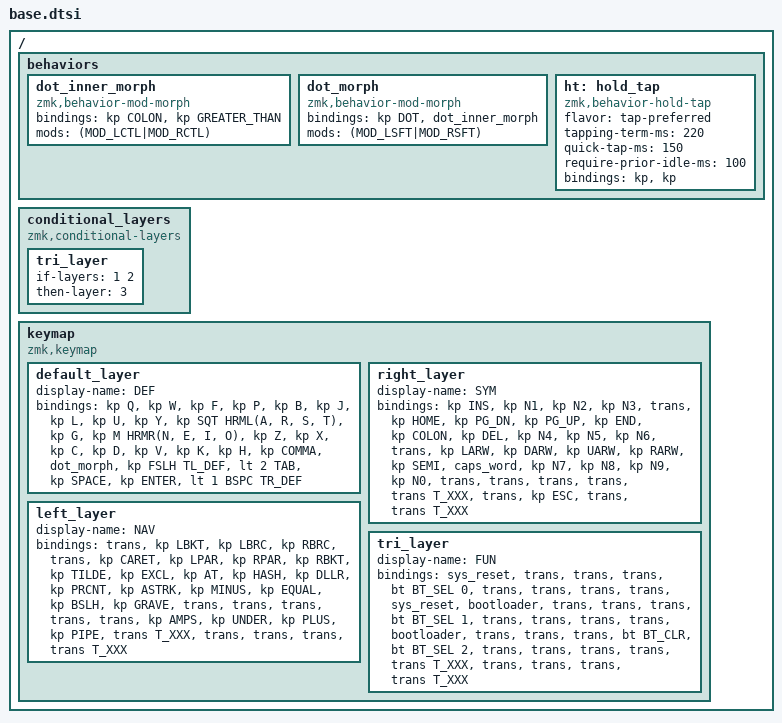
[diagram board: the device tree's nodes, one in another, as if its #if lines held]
// vim: set ts=2 sw=2 ft=devicetree:

#include <behaviors.dtsi>
#include <dt-bindings/zmk/keys.h>
#include <dt-bindings/zmk/bt.h>

//layers definitions
#define DEF 0
#define SYM 1
#define NAV 2
#define FUN 3

// Now import if any extra external layers needed
#include "combos.dtsi"

#ifdef THREE_THUMBS
#  define TL_DEF &mt LGUI TAB
#  define TR_DEF &mt RALT DEL
#  define T_XXX &none
#else
#  define TL_DEF
#  define TR_DEF
#  define T_XXX
#endif

// Home row mods macro
// GUI -> ALT -> CTRL -> SHFT    |    SHFT -> CTRL -> ALT -> GUI
#define HRML(k1,k2,k3,k4) &ht LGUI  k1 &ht LALT  k2 &ht LCTRL k3 &ht LSHFT k4
#define HRMR(k1,k2,k3,k4) &ht RSHFT k1 &ht RCTRL k2 &ht RALT  k3 &ht RGUI  k4

// tap: dot | shift + tap: colon | ctrl + shift + tap: >
/ {
    behaviors {
        dot_inner_morph: dot_inner_morph {
            compatible = "zmk,behavior-mod-morph";
            bindings = <&kp COLON>, <&kp GREATER_THAN>;
            mods = <(MOD_LCTL|MOD_RCTL)>;
        };
        dot_morph: dot_morph {
            compatible = "zmk,behavior-mod-morph";
            bindings = <&kp DOT>, <&dot_inner_morph>;
            mods = <(MOD_LSFT|MOD_RSFT)>;
        };
    };
};

/ {
    behaviors {
        ht: hold_tap {
            compatible = "zmk,behavior-hold-tap";
            #binding-cells = <2>;
            flavor = "tap-preferred";
            tapping-term-ms = <220>;
            quick-tap-ms = <150>;
            require-prior-idle-ms = <100>;
            bindings = <&kp>, <&kp>;
        };
    };

    conditional_layers {
        compatible = "zmk,conditional-layers";
        tri_layer {
            if-layers = <1 2>;
            then-layer = <3>;
        };
    };

    keymap {
        compatible = "zmk,keymap";
        default_layer {
            display-name = "DEF";
            bindings = <
        //╭──────────┬──────────┬──────────┬──────────┬──────────╮   ╭──────────┬──────────┬──────────┬──────────┬──────────╮
            &kp Q      &kp W      &kp F      &kp P      &kp B          &kp J      &kp L      &kp U      &kp Y      &kp SQT
        //├──────────┼──────────┼──────────┼──────────┼──────────┤   ├──────────┼──────────┼──────────┼──────────┼──────────┤
            HRML(A,        R,         S,         T)     &kp G          &kp M      HRMR(N,        E,         I,        O)
        //├──────────┼──────────┼──────────┼──────────┼──────────┤   ├──────────┼──────────┼──────────┼──────────┼──────────┤
            &kp Z      &kp X      &kp C      &kp D      &kp V          &kp K      &kp H      &kp COMMA  &dot_morph &kp FSLH
        //╰──────────┴──────────┴──────────┼──────────┼──────────┤   ├──────────┼──────────┼──────────┴──────────┴──────────╯
                                  TL_DEF    &lt 2 TAB   &kp SPACE     &kp ENTER   &lt 1 BSPC  TR_DEF
        //                      ╰──────────┴──────────┴──────────╯   ╰──────────┴──────────┴──────────╯
            >;
        };

        right_layer {
            display-name = "SYM";
            bindings = <
        //╭──────────┬──────────┬──────────┬──────────┬──────────╮   ╭──────────┬──────────┬──────────┬──────────┬──────────╮
            &kp INS    &kp N1     &kp N2     &kp N3     &trans         &kp HOME   &kp PG_DN  &kp PG_UP  &kp END    &kp COLON
        //├──────────┼──────────┼──────────┼──────────┼──────────┤   ├──────────┼──────────┼──────────┼──────────┼──────────┤
            &kp DEL    &kp N4     &kp N5     &kp N6     &trans         &kp LARW   &kp DARW   &kp UARW   &kp RARW   &kp SEMI
        //├──────────┼──────────┼──────────┼──────────┼──────────┤   ├──────────┼──────────┼──────────┼──────────┼──────────┤
           &caps_word  &kp N7     &kp N8     &kp N9     &kp N0         &trans     &trans     &trans     &trans     &trans
        //╰──────────┴──────────┴──────────┼──────────┼──────────┤   ├──────────┼──────────┼──────────┴──────────┴──────────╯
                                  T_XXX      &trans     &kp ESC        &trans     &trans     T_XXX
        //                      ╰──────────┴──────────┴──────────╯   ╰──────────┴──────────┴──────────╯
            >;
        };

        left_layer {
            display-name = "NAV";
            bindings = <
        //╭──────────┬──────────┬──────────┬──────────┬──────────╮   ╭──────────┬──────────┬──────────┬──────────┬──────────╮
            &trans     &kp LBKT   &kp LBRC   &kp RBRC   &trans         &kp CARET  &kp LPAR   &kp RPAR   &kp RBKT   &kp TILDE
        //├──────────┼──────────┼──────────┼──────────┼──────────┤   ├──────────┼──────────┼──────────┼──────────┼──────────┤
            &kp EXCL   &kp AT     &kp HASH   &kp DLLR   &kp PRCNT      &kp ASTRK  &kp MINUS  &kp EQUAL  &kp BSLH   &kp GRAVE
        //├──────────┼──────────┼──────────┼──────────┼──────────┤   ├──────────┼──────────┼──────────┼──────────┼──────────┤
            &trans     &trans     &trans     &trans     &trans         &kp AMPS   &kp UNDER  &kp PLUS   &kp PIPE   &trans
        //╰──────────┴──────────┴──────────┼──────────┼──────────┤   ├──────────┼──────────┼──────────┴──────────┴──────────╯
                                  T_XXX      &trans     &trans         &trans     &trans     T_XXX
        //                      ╰──────────┴──────────┴──────────╯   ╰──────────┴──────────┴──────────╯
            >;
        };

        tri_layer {
            display-name = "FUN";
            bindings = <
        //╭──────────┬──────────┬──────────┬──────────┬──────────╮   ╭──────────┬──────────┬──────────┬──────────┬──────────╮
           &sys_reset  &trans     &trans     &trans    &bt BT_SEL 0    &trans     &trans     &trans     &trans    &sys_reset
        //├──────────┼──────────┼──────────┼──────────┼──────────┤   ├──────────┼──────────┼──────────┼──────────┼──────────┤
          &bootloader  &trans     &trans     &trans    &bt BT_SEL 1    &trans     &trans     &trans     &trans    &bootloader
        //├──────────┼──────────┼──────────┼──────────┼──────────┤   ├──────────┼──────────┼──────────┼──────────┼──────────┤
            &trans     &trans     &trans    &bt BT_CLR &bt BT_SEL 2    &trans     &trans     &trans     &trans     &trans
        //╰──────────┴──────────┴──────────┼──────────┼──────────┤   ├──────────┼──────────┼──────────┴──────────┴──────────╯
                                  T_XXX      &trans     &trans         &trans     &trans     T_XXX
        //                      ╰──────────┴──────────┴──────────╯   ╰──────────┴──────────┴──────────╯
            >;
        };
    };
};
